VERSION ""

NS_ :

BS_:

BU_: Arduino External

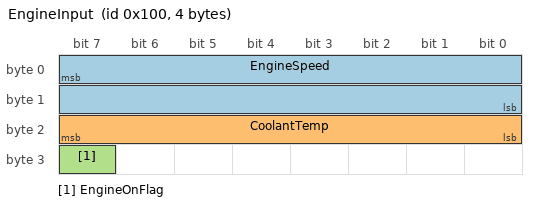
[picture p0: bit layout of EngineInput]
BO_ 256 EngineInput: 4 External
 SG_ EngineSpeed  : 7|16@0+ (1,0) [0|15000] "rpm"  Arduino
 SG_ CoolantTemp  : 23|8@0+ (1,0) [0|255]   "degC" Arduino
 SG_ EngineOnFlag : 31|1@0+ (1,0) [0|1]     ""     Arduino

BO_ 512 EngineStatus: 1 Arduino
 SG_ EngineState  : 7|8@0+  (1,0) [0|3]     ""     External

BO_ 2016 UdsDiagRequest: 8 External
 SG_ Pci       : 7|8@0+  (1,0) [0|255] "" Arduino
 SG_ ServiceId : 15|8@0+ (1,0) [0|255] "" Arduino

BO_ 2024 UdsDiagResponse: 8 Arduino
 SG_ Pci       : 7|8@0+  (1,0) [0|255] "" External
 SG_ ServiceId : 15|8@0+ (1,0) [0|255] "" External

CM_ BO_ 256  "RX: External -> Arduino (CAN ID 0x100)";
CM_ BO_ 512  "TX: Arduino -> External (CAN ID 0x200)";
CM_ BO_ 2016 "TX: External -> Arduino (CAN ID 0x7E0) UDS diagnostic request (ISO 14229-1). Single Frame only (ISO 15765-2). Pci=0x0N (N=UDS payload length), ServiceId=SID.";
CM_ BO_ 2024 "TX: Arduino -> External (CAN ID 0x7E8) UDS diagnostic response. Positive: ServiceId = request SID + 0x40. Negative: ServiceId=0x7F, byte[2]=failed SID, byte[3]=NRC.";

CM_ SG_ 256 EngineSpeed  "Engine speed [rpm]. STARTING->RUNNING when >= 500. RUNNING->FAULT when < 100.";
CM_ SG_ 256 CoolantTemp  "Coolant temperature [degC]. RUNNING->FAULT when >= 100.";
CM_ SG_ 256 EngineOnFlag "Engine on request. OFF->STARTING when 1. Any state->OFF when 0.";
CM_ SG_ 512 EngineState  "Current engine state reported by Arduino every 3 seconds.";

CM_ SG_ 2016 Pci       "ISO 15765-2 PCI byte. Upper nibble=frame type (0x0=SingleFrame). Lower nibble=UDS payload length (1-7).";
CM_ SG_ 2016 ServiceId "UDS Service ID (SID). 0x10=DiagnosticSessionControl, 0x11=ECUReset, 0x22=ReadDataByIdentifier, 0x3E=TesterPresent.";
CM_ SG_ 2024 Pci       "ISO 15765-2 PCI byte. Upper nibble=frame type (0x0=SingleFrame). Lower nibble=UDS payload length.";
CM_ SG_ 2024 ServiceId "UDS Response SID. Positive = request SID + 0x40. 0x50=SessionCtrl_Pos, 0x51=ECUReset_Pos, 0x62=ReadData_Pos, 0x7E=TesterPresent_Pos, 0x7F=NegativeResponse.";

 0 "OFF"
 1 "ON" ;

 0 "OFF"
 1 "STARTING"
 2 "RUNNING"
 3 "FAULT" ;

 16  "DiagnosticSessionControl"
 17  "ECUReset"
 34  "ReadDataByIdentifier"
 62  "TesterPresent" ;

 80  "DiagnosticSessionControl_Pos"
 81  "ECUReset_Pos"
 98  "ReadDataByIdentifier_Pos"
 126 "TesterPresent_Pos"
 127 "NegativeResponse" ;
